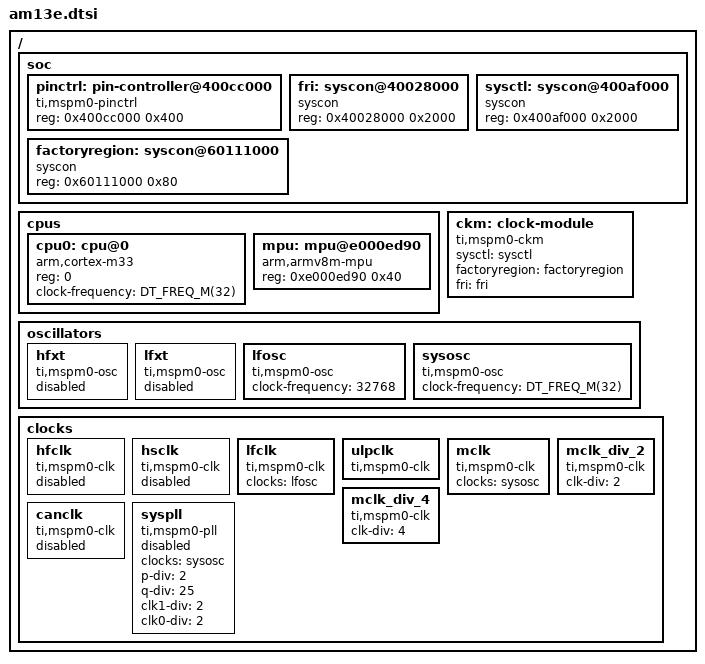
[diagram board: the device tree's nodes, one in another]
/*
 * Copyright (c) 2026 Texas Instruments Incorporated
 *
 * SPDX-License-Identifier: Apache-2.0
 */

#include <arm/armv8-m.dtsi>
#include <mem.h>
#include <freq.h>

/ {
	soc {
		pinctrl: pin-controller@400cc000 {
			compatible = "ti,mspm0-pinctrl";
			reg = <0x400cc000 0x400>;
		};
	};

	cpus {
		#address-cells = <1>;
		#size-cells = <0>;

		cpu0: cpu@0 {
			compatible = "arm,cortex-m33";
			reg = <0>;
			device_type = "cpu";
			#address-cells = <1>;
			#size-cells = <1>;
			clock-frequency = <DT_FREQ_M(32)>;
		};

		mpu: mpu@e000ed90 {
			compatible = "arm,armv8m-mpu";
			reg = <0xe000ed90 0x40>;
		};
	};

	ckm: clock-module {
		compatible = "ti,mspm0-ckm";
		#clock-cells = <1>;
		sysctl = <&sysctl>;
		factoryregion = <&factoryregion>;
		fri = <&fri>;
	};

	oscillators: oscillators {
		hfxt: hfxt {
			compatible = "ti,mspm0-osc";
			#clock-cells = <0>;
			status = "disabled";
		};

		lfxt: lfxt {
			compatible = "ti,mspm0-osc";
			#clock-cells = <0>;
			status = "disabled";
		};

		lfosc: lfosc {
			compatible = "ti,mspm0-osc";
			#clock-cells = <0>;
			clock-frequency = <32768>;
		};

		sysosc: sysosc {
			compatible = "ti,mspm0-osc";
			#clock-cells = <0>;
			clock-frequency = <DT_FREQ_M(32)>;
		};
	};

	clocks: clocks {
		hfclk: hfclk {
			compatible = "ti,mspm0-clk";
			#clock-cells = <0>;
			status = "disabled";
		};

		hsclk: hsclk {
			compatible = "ti,mspm0-clk";
			#clock-cells = <0>;
			status = "disabled";
		};

		lfclk: lfclk {
			compatible = "ti,mspm0-clk";
			#clock-cells = <0>;
			clocks = <&lfosc>;
		};

		ulpclk: ulpclk {
			compatible = "ti,mspm0-clk";
			#clock-cells = <0>;
		};

		mclk: mclk {
			compatible = "ti,mspm0-clk";
			#clock-cells = <0>;
			clocks = <&sysosc>;
		};

		mclk_div_2: mclk_div_2 {
			compatible = "ti,mspm0-clk";
			#clock-cells = <0>;
			clk-div = <2>;
		};

		mclk_div_4: mclk_div_4 {
			compatible = "ti,mspm0-clk";
			#clock-cells = <0>;
			clk-div = <4>;
		};

		canclk: canclk {
			compatible = "ti,mspm0-clk";
			#clock-cells = <0>;
			status = "disabled";
		};

		syspll: syspll {
			compatible = "ti,mspm0-pll";
			clocks = <&sysosc>;
			p-div = <2>;
			q-div = <25>;
			clk1-div = <2>;
			clk0-div = <2>;
			#clock-cells = <0>;
			status = "disabled";
		};
	};

	soc {
		fri: syscon@40028000 {
			compatible = "syscon";
			reg = <0x40028000 0x2000>;
		};

		sysctl: syscon@400af000 {
			compatible = "syscon";
			reg = <0x400af000 0x2000>;
			status = "okay";
		};

		factoryregion: syscon@60111000 {
			compatible = "syscon";
			reg = <0x60111000 0x80>;
		};
	};
};
